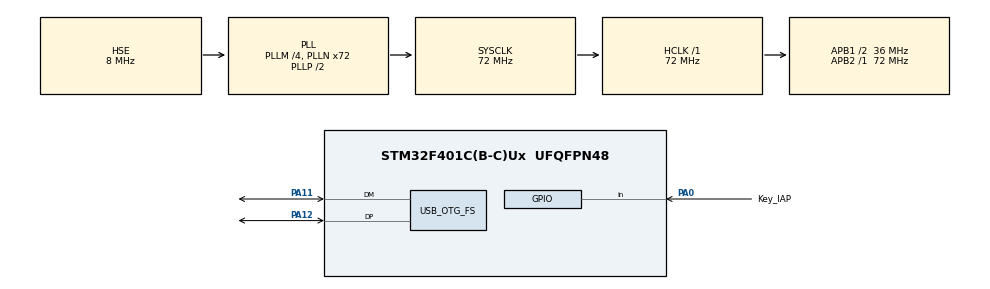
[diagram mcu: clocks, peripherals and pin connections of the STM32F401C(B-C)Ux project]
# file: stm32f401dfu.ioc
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Mcu.Family=STM32F4
Mcu.Name=STM32F401C(B-C)Ux
Mcu.Package=UFQFPN48
NVIC.OTG_FS_IRQn=true\:0\:0\:false\:false\:true\:false\:true
NVIC.PriorityGroup=NVIC_PRIORITYGROUP_4
PA0-WKUP.GPIO_Label=Key_IAP
PA0-WKUP.GPIO_PuPd=GPIO_PULLUP
PA0-WKUP.Signal=GPIO_Input
PA11.Mode=Device_Only
PA11.Signal=USB_OTG_FS_DM
PA12.Mode=Device_Only
PA12.Signal=USB_OTG_FS_DP
PA13.Mode=Serial_Wire
PA13.Signal=SYS_JTMS-SWDIO
PA14.Mode=Serial_Wire
PA14.Signal=SYS_JTCK-SWCLK
PC14-OSC32_IN.Mode=LSE-External-Oscillator
PC14-OSC32_IN.Signal=RCC_OSC32_IN
PC15-OSC32_OUT.Mode=LSE-External-Oscillator
PC15-OSC32_OUT.Signal=RCC_OSC32_OUT
PH0\ -\ OSC_IN.Mode=HSE-External-Oscillator
PH0\ -\ OSC_IN.Signal=RCC_OSC_IN
PH1\ -\ OSC_OUT.Mode=HSE-External-Oscillator
PH1\ -\ OSC_OUT.Signal=RCC_OSC_OUT
ProjectManager.HeapSize=0x2000
ProjectManager.StackSize=0x1000
ProjectManager.TargetToolchain=MDK-ARM V5
RCC.48MHZClocksFreq_Value=48000000
RCC.AHBFreq_Value=72000000
RCC.APB1CLKDivider=RCC_HCLK_DIV2
RCC.APB1Freq_Value=36000000
RCC.APB1TimFreq_Value=72000000
RCC.APB2Freq_Value=72000000
RCC.APB2TimFreq_Value=72000000
RCC.CortexFreq_Value=72000000
RCC.HCLKFreq_Value=72000000
RCC.HSE_VALUE=8000000
RCC.HSI_VALUE=16000000
RCC.PLLM=4
RCC.PLLN=72
RCC.PLLQ=3
RCC.SYSCLKFreq_VALUE=72000000
RCC.SYSCLKSource=RCC_SYSCLKSOURCE_PLLCLK
RCC.VCOOutputFreq_Value=144000000
USB_DEVICE.CLASS_NAME_FS=DFU
USB_DEVICE.USBD_DEBUG_LEVEL=2
USB_DEVICE.USBD_DFU_APP_DEFAULT_ADD=0x0800C000
USB_DEVICE.USBD_DFU_MEDIA=@Internal Flash   /0x08000000/03*016Ka,01*016Kg,01*064Kg,01*128Kg
USB_DEVICE.VirtualMode=Dfu
USB_DEVICE.VirtualModeFS=Dfu_FS
USB_OTG_FS.VirtualMode=Device_Only
VP_USB_DEVICE_VS_USB_DEVICE_DFU_FS.Mode=DFU_FS
board=custom

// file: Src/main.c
/* USER CODE BEGIN Header */
/**
  ******************************************************************************
  * @file           : main.c
  * @brief          : Main program body
  ******************************************************************************
  * @attention
  *
  * <h2><center>&copy; Copyright (c) 2019 STMicroelectronics.
  * All rights reserved.</center></h2>
  *
  * This software component is licensed by ST under Ultimate Liberty license
  * SLA0044, the "License"; You may not use this file except in compliance with
  * the License. You may obtain a copy of the License at:
  *                             www.st.com/SLA0044
  *
  ******************************************************************************
  */
/* USER CODE END Header */

#include "main.h"
#include "usb_device.h"
#include "gpio.h"

/* USER CODE BEGIN Includes */
#include "usbd_dfu.h"
/* USER CODE END Includes */

/* USER CODE BEGIN PV */
pFunction JumpToApplication;
uint32_t JumpAddress;
/* USER CODE END PV */

void SystemClock_Config(void);

int main(void)
{

  /* MCU Configuration--------------------------------------------------------*/

  /* Reset of all peripherals, Initializes the Flash interface and the Systick. */
  HAL_Init();

  /* Configure the system clock */
  SystemClock_Config();

  /* Initialize all configured peripherals */
  MX_GPIO_Init();
  //MX_USB_DEVICE_Init();
  /* USER CODE BEGIN 2 */
	HAL_Delay(100);
	if(HAL_GPIO_ReadPin( Key_IAP_GPIO_Port , Key_IAP_Pin ) == GPIO_PIN_SET)
	{
        /* Test if user code is programmed starting from USBD_DFU_APP_DEFAULT_ADD address */
        if(((*(__IO uint32_t*)USBD_DFU_APP_DEFAULT_ADD) & 0x2FFE0000 ) == 0x20000000)
        {
            /* Jump to user application */
            JumpAddress = *(__IO uint32_t*) (USBD_DFU_APP_DEFAULT_ADD + 4);
            JumpToApplication = (pFunction) JumpAddress;

            /* Initialize user application's Stack Pointer */
            __set_MSP(*(__IO uint32_t*) USBD_DFU_APP_DEFAULT_ADD);
            JumpToApplication();
        }
    }

    MX_USB_DEVICE_Init();
  /* USER CODE END 2 */

  /* Infinite loop */
  while (1)
  {
  }
}

void SystemClock_Config(void)
{
  RCC_OscInitTypeDef RCC_OscInitStruct = {0};
  RCC_ClkInitTypeDef RCC_ClkInitStruct = {0};

  /** Configure the main internal regulator output voltage
  */
  __HAL_RCC_PWR_CLK_ENABLE();
  __HAL_PWR_VOLTAGESCALING_CONFIG(PWR_REGULATOR_VOLTAGE_SCALE2);
  /** Initializes the CPU, AHB and APB busses clocks
  */
  RCC_OscInitStruct.OscillatorType = RCC_OSCILLATORTYPE_HSE;
  RCC_OscInitStruct.HSEState = RCC_HSE_ON;
  RCC_OscInitStruct.PLL.PLLState = RCC_PLL_ON;
  RCC_OscInitStruct.PLL.PLLSource = RCC_PLLSOURCE_HSE;
  RCC_OscInitStruct.PLL.PLLM = 4;
  RCC_OscInitStruct.PLL.PLLN = 72;
  RCC_OscInitStruct.PLL.PLLP = RCC_PLLP_DIV2;
  RCC_OscInitStruct.PLL.PLLQ = 3;
  if (HAL_RCC_OscConfig(&RCC_OscInitStruct) != HAL_OK)
  {
    Error_Handler();
  }
  /** Initializes the CPU, AHB and APB busses clocks
  */
  RCC_ClkInitStruct.ClockType = RCC_CLOCKTYPE_HCLK|RCC_CLOCKTYPE_SYSCLK
                              |RCC_CLOCKTYPE_PCLK1|RCC_CLOCKTYPE_PCLK2;
  RCC_ClkInitStruct.SYSCLKSource = RCC_SYSCLKSOURCE_PLLCLK;
  RCC_ClkInitStruct.AHBCLKDivider = RCC_SYSCLK_DIV1;
  RCC_ClkInitStruct.APB1CLKDivider = RCC_HCLK_DIV2;
  RCC_ClkInitStruct.APB2CLKDivider = RCC_HCLK_DIV1;

  if (HAL_RCC_ClockConfig(&RCC_ClkInitStruct, FLASH_LATENCY_2) != HAL_OK)
  {
    Error_Handler();
  }
}

void Error_Handler(void)
{
}

/************************ (C) COPYRIGHT STMicroelectronics *****END OF FILE****/
